# ATSAML11E16A register map
Vendor: Microchip Technology; Series: SAML11; File version: 0
CPU: CM23 r0p0, selectable endian, MPU, no FPU, 2 interrupt priority bits
Registers are 32-bit, read-write, reset 0x0 unless marked. A register's access mark holds for its fields unless they carry their own. Offsets are from the block's base; [hi:lo] are bit positions; {n}, {i} and the like mark numbered series; 'fields as' and 'values as' point back to an identical list.

## OPAMP — Operational Amplifier
Base 0x42003000; register names take the prefix OPAMP_
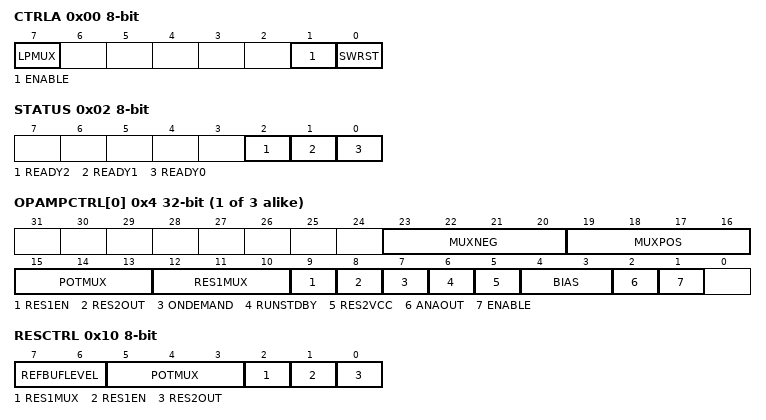
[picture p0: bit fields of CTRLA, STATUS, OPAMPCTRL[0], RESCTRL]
0x00 CTRLA 8-bit — Control A
  [7] LPMUX — Low-Power Mux
  [1] ENABLE
  [0] SWRST — Software Reset
0x02 STATUS 8-bit ro
  [2] READY2 — OPAMP 2 Ready
  [1] READY1 — OPAMP 1 Ready
  [0] READY0 — OPAMP 0 Ready
{0x4+4i} OPAMPCTRL[{i}] (i=0..2) — OPAMP n Control
  [23:20] MUXNEG — Negative Input Mux Selection
  [19:16] MUXPOS — Positive Input Mux Selection
  [15:13] POTMUX — Potentiometer Selection
  [12:10] RES1MUX — Resistor 1 Mux
  [9] RES1EN — Resistor 1 Enable
  [8] RES2OUT — Resistor ladder To Output
  [7] ONDEMAND — On Demand Control
  [6] RUNSTDBY — Run in Standby
  [5] RES2VCC — Resistor ladder To VCC
  [4:3] BIAS — Bias Selection
  [2] ANAOUT — Analog Output
  [1] ENABLE — Operational Amplifier Enable
0x10 RESCTRL 8-bit — Resister Control
  [7:6] REFBUFLEVEL — Reference output voltage level select
  [5:3] POTMUX — Potentiometer Selection
  [2] RES1MUX — Resistor 1 Mux
  [1] RES1EN — Resistor 1 Enable
  [0] RES2OUT — Resistor ladder To Output

## OSC32KCTRL — 32k Oscillators Control
Base 0x40001400; register names take the prefix OSC32KCTRL_
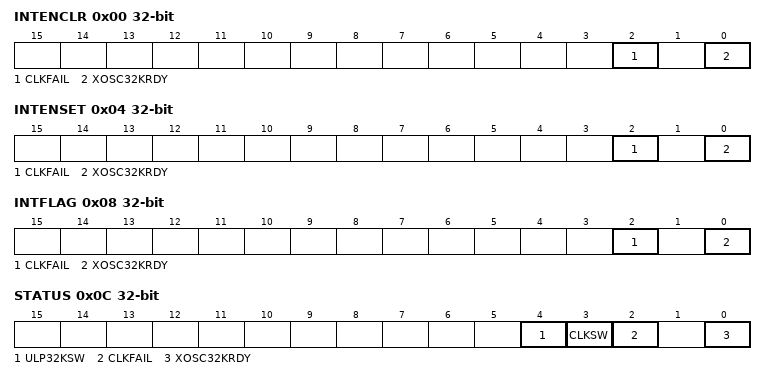
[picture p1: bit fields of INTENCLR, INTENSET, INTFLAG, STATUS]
0x00 INTENCLR — Interrupt Enable Clear
  [2] CLKFAIL — XOSC32K Clock Failure Detector Interrupt Enable
  [0] XOSC32KRDY — XOSC32K Ready Interrupt Enable
0x04 INTENSET — Interrupt Enable Set
  fields as INTENCLR
0x08 INTFLAG — Interrupt Flag Status and Clear
  [2] CLKFAIL — XOSC32K Clock Failure Detector
  [0] XOSC32KRDY — XOSC32K Ready
0x0C STATUS ro — Power and Clocks Status
  [4] ULP32KSW — OSCULP32K Clock Switch
  [3] CLKSW — XOSC32K Clock switch
  [2] CLKFAIL — XOSC32K Clock Failure Detector
  [0] XOSC32KRDY — XOSC32K Ready
0x10 RTCCTRL 8-bit — RTC Clock Selection
  [2:0] RTCSEL
    0=ULP1K (1.024kHz from 32kHz internal ULP oscillator); 1=ULP32K (32.768kHz from 32kHz internal ULP oscillator); 2=OSC1K (1.024kHz from 32.768kHz internal oscillator); 3=OSC32K (32.768kHz from 32.768kHz internal oscillator); 4=XOSC1K (1.024kHz from 32.768kHz internal oscillator); 5=XOSC32K (32.768kHz from 32.768kHz external crystal oscillator)
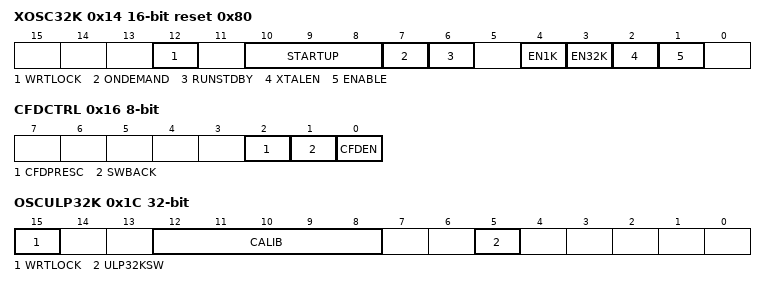
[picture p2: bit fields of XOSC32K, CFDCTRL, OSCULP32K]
0x14 XOSC32K 16-bit reset 0x80 — 32kHz External Crystal Oscillator (XOSC32K) Control
  [12] WRTLOCK — Write Lock
  [10:8] STARTUP — Oscillator Start-Up Time
  [7] ONDEMAND — On Demand Control
  [6] RUNSTDBY — Run in Standby
  [4] EN1K — 1kHz Output Enable
  [3] EN32K — 32kHz Output Enable
  [2] XTALEN — Crystal Oscillator Enable
  [1] ENABLE — Oscillator Enable
0x16 CFDCTRL 8-bit — Clock Failure Detector Control
  [2] CFDPRESC — Clock Failure Detector Prescaler
  [1] SWBACK — Clock Switch Back
  [0] CFDEN — Clock Failure Detector Enable
0x17 EVCTRL 8-bit — Event Control
  [0] CFDEO — Clock Failure Detector Event Output Enable
0x1C OSCULP32K — 32kHz Ultra Low Power Internal Oscillator (OSCULP32K) Control
  [15] WRTLOCK — Write Lock
  [12:8] CALIB — Oscillator Calibration
  [5] ULP32KSW — OSCULP32K Clock Switch Enable

## PM — Power Manager
Base 0x40000400; register names take the prefix PM_
0x01 SLEEPCFG 8-bit reset 0x2 — Sleep Configuration
  [2:0] SLEEPMODE
    2=IDLE (CPU, AHB, APB clocks are OFF); 4=STANDBY (All Clocks are OFF); 6=OFF (All power domains are powered OFF)
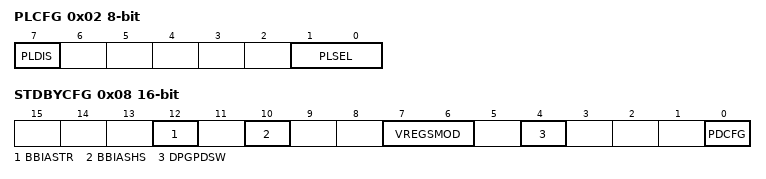
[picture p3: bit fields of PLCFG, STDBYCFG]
0x02 PLCFG 8-bit — Performance Level Configuration
  [7] PLDIS — Performance Level Disable
  [1:0] PLSEL — Performance Level Select
    0=PL0 (Performance Level 0); 2=PL2 (Performance Level 2)
0x03 PWCFG 8-bit — Power Configuration
  [1:0] RAMPSWC — RAM Power Switch Configuration
    0=16KB (16KB Available); 1=12KB (12KB Available); 2=8KB (8KB Available); 3=4KB (4KB Available)
0x04 INTENCLR 8-bit — Interrupt Enable Clear
  [0] PLRDY — Performance Level Interrupt Enable
0x05 INTENSET 8-bit — Interrupt Enable Set
  [0] PLRDY — Performance Level Ready interrupt Enable
0x06 INTFLAG 8-bit — Interrupt Flag Status and Clear
  [0] PLRDY — Performance Level Ready
0x08 STDBYCFG 16-bit — Standby Configuration
  [12] BBIASTR — Back Bias for Trust RAM
  [10] BBIASHS — Back Bias for HSRAM
  [7:6] VREGSMOD — Voltage Regulator Standby mode
    0=AUTO (Automatic mode); 1=PERFORMANCE (Performance oriented); 2=LP (Low Power oriented)
  [4] DPGPDSW — Dynamic Power Gating for PDSW
    0=Dynamic Power Gating disabled; 1=Dynamic Power Gating enabled
  [0] PDCFG — Power Domain Configuration
    0=DEFAULT (PDSW power domain switching is handled by hardware.); 1=PDSW (PDSW is forced ACTIVE.)

## Notices in the file
Copyright (c) 2017 Microchip Technology Inc.
SPDX-License-Identifier: Apache-2.0
Licensed under the Apache License, Version 2.0 (the "License");
you may not use this file except in compliance with the License.
You may obtain a copy of the License at
http://www.apache.org/licenses/LICENSE-2.0
Unless required by applicable law or agreed to in writing, software
distributed under the License is distributed on an "AS IS" BASIS,
WITHOUT WARRANTIES OR CONDITIONS OF ANY KIND, either express or implied.
See the License for the specific language governing permissions and
limitations under the License.
